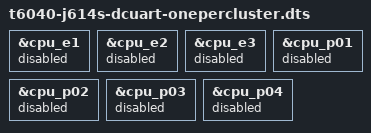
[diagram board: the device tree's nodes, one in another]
// SPDX-License-Identifier: GPL-2.0+ OR MIT
/*
 * Ticket 205 discriminator: THREE CPUs, one in each cluster.
 *
 * The sdroot.shell reproducer puts the CoW fault threshold between 2 and 3:
 *   maxcpus=2 -> clean (0 traces, 0 panics)
 *   maxcpus=3 -> SIGSEGV in copy_page/do_wp_page + panic
 *
 * Linux numbering here is cpu0 = P00 (boot, part 0x055), cpu1..4 = the four E
 * cores (part 0x054), cpu5..8 = P01..P04, cpu9..13 = P10..P14. So maxcpus=2 is
 * P00 + E0 -- two DIFFERENT clusters -- while maxcpus=3 adds E1, the first time
 * two online CPUs SHARE a cluster (and therefore a shared L2).
 *
 * Hypothesis: the corruption requires two CPUs inside one cluster, i.e. it is
 * intra-cluster cache maintenance rather than core count.
 *
 * This DT fails every E core except E0 and every P0 sibling, so the first three
 * CPUs Linux brings up are P00 + E0 + P10 -- one per cluster, no sharing.
 *   boots clean at maxcpus=3 -> intra-cluster sharing is the trigger; the fix is
 *     a cache/TLB maintenance bug, and a 3-core daily driver is available now.
 *   still faults            -> it is plain core count, and the hypothesis dies.
 */
#include "t6040-j614s-dcuart-wifi-cpufreq.dts"

/* E cluster: keep only E0 */
&cpu_e1 { status = "fail"; };
&cpu_e2 { status = "fail"; };
&cpu_e3 { status = "fail"; };

/* P cluster 0: keep only the boot core (cpu_p00) */
&cpu_p01 { status = "fail"; };
&cpu_p02 { status = "fail"; };
&cpu_p03 { status = "fail"; };
&cpu_p04 { status = "fail"; };
